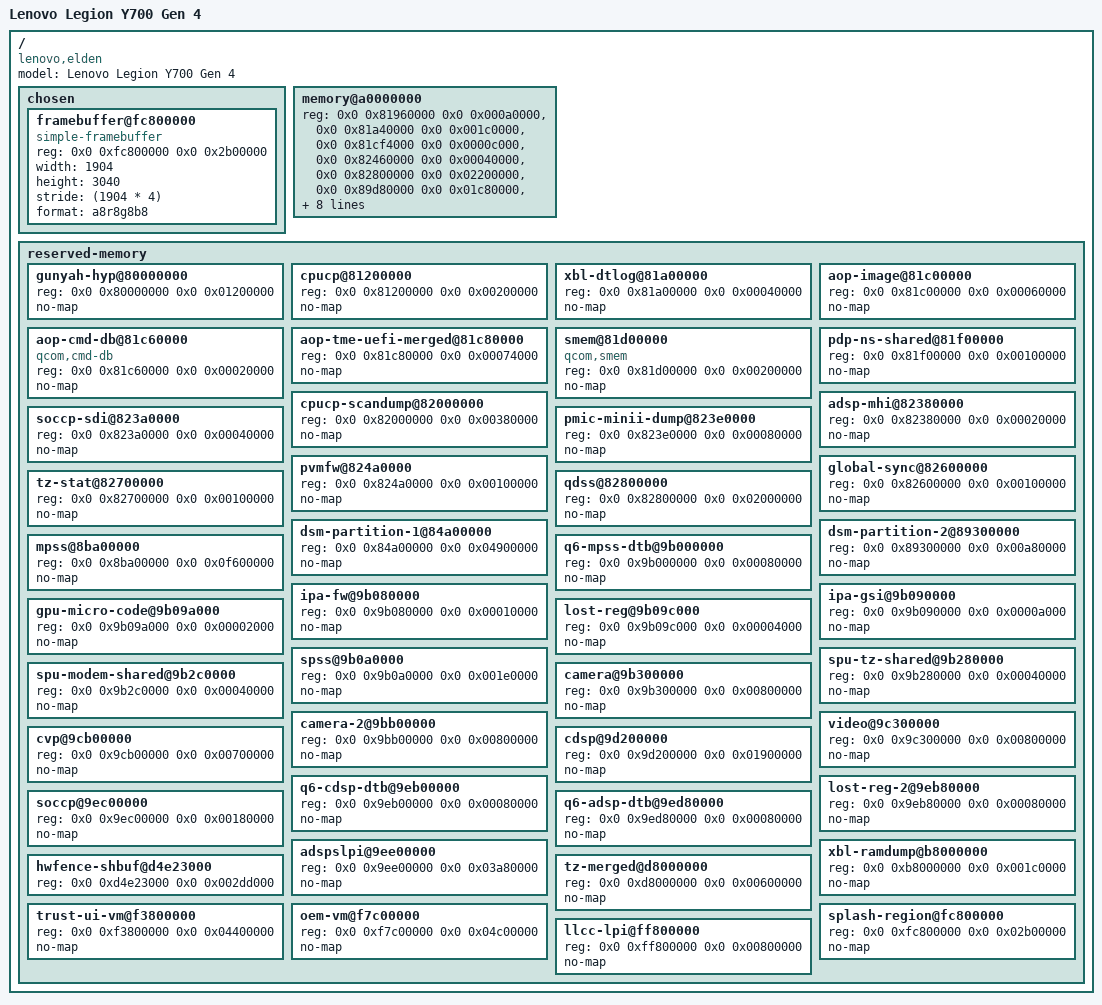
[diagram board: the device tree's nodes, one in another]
// SPDX-License-Identifier: BSD-3-Clause
//
// Sanitised elden firmware memory handoff description.
//
// This is not the raw FDT copied from a device and it is not installed into
// the phase 1 firmware. It normalises the live 12 GiB memory and reserved
// ranges captured from the target device, cross-checked against:
//
//   h0cheung/tb322fc-linux-kernel
//   arch/arm64/boot/dts/qcom/sm8750-lenovo-elden.dts
//   commit 6f97250ead155fc3b980856323e99a4623dae73d
//
// The raw device tree is local-only. This sanitised source allows the memory
// and framebuffer handoff to be reviewed, compiled and compared with a live
// FDT without publishing a device state dump.

/dts-v1/;

/ {
	model = "Lenovo Legion Y700 Gen 4";
	compatible = "lenovo,elden", "qcom,sm8750";
	#address-cells = <2>;
	#size-cells = <2>;

	chosen {
		#address-cells = <2>;
		#size-cells = <2>;
		ranges;

		framebuffer@fc800000 {
			compatible = "simple-framebuffer";
			reg = <0x0 0xfc800000 0x0 0x2b00000>;
			width = <1904>;
			height = <3040>;
			stride = <(1904 * 4)>;
			format = "a8r8g8b8";
		};
	};

	// Exact non-empty RAM ranges from the captured live FDT. The zero-length
	// D8600000 placeholder is intentionally omitted.
	memory@a0000000 {
		device_type = "memory";
		reg = <0x0 0x81960000 0x0 0x000a0000>,
		      <0x0 0x81a40000 0x0 0x001c0000>,
		      <0x0 0x81cf4000 0x0 0x0000c000>,
		      <0x0 0x82460000 0x0 0x00040000>,
		      <0x0 0x82800000 0x0 0x02200000>,
		      <0x0 0x89d80000 0x0 0x01c80000>,
		      <0x0 0xa2880000 0x0 0x15780000>,
		      <0x0 0xb81c0000 0x0 0x1cc63000>,
		      <0x0 0xd5100000 0x0 0x02f00000>,
		      <0x0 0xe3720000 0x0 0x1c0e0000>,
		      <0x8 0x80000000 0x0 0x2f900000>,
		      <0x8 0xb0000000 0x0 0x07500000>,
		      <0x8 0xc0000000 0x0 0xc0000000>,
		      <0x9 0x80000000 0x1 0x80000000>;
	};

	reserved-memory {
		#address-cells = <2>;
		#size-cells = <2>;
		ranges;

		gunyah-hyp@80000000 {
			reg = <0x0 0x80000000 0x0 0x01200000>;
			no-map;
		};

		cpucp@81200000 {
			reg = <0x0 0x81200000 0x0 0x00200000>;
			no-map;
		};

		xbl-dtlog@81a00000 {
			reg = <0x0 0x81a00000 0x0 0x00040000>;
			no-map;
		};

		aop-image@81c00000 {
			reg = <0x0 0x81c00000 0x0 0x00060000>;
			no-map;
		};

		aop-cmd-db@81c60000 {
			compatible = "qcom,cmd-db";
			reg = <0x0 0x81c60000 0x0 0x00020000>;
			no-map;
		};

		aop-tme-uefi-merged@81c80000 {
			reg = <0x0 0x81c80000 0x0 0x00074000>;
			no-map;
		};

		smem@81d00000 {
			compatible = "qcom,smem";
			reg = <0x0 0x81d00000 0x0 0x00200000>;
			no-map;
		};

		pdp-ns-shared@81f00000 {
			reg = <0x0 0x81f00000 0x0 0x00100000>;
			no-map;
		};

		cpucp-scandump@82000000 {
			reg = <0x0 0x82000000 0x0 0x00380000>;
			no-map;
		};

		adsp-mhi@82380000 {
			reg = <0x0 0x82380000 0x0 0x00020000>;
			no-map;
		};

		soccp-sdi@823a0000 {
			reg = <0x0 0x823a0000 0x0 0x00040000>;
			no-map;
		};

		pmic-minii-dump@823e0000 {
			reg = <0x0 0x823e0000 0x0 0x00080000>;
			no-map;
		};

		pvmfw@824a0000 {
			reg = <0x0 0x824a0000 0x0 0x00100000>;
			no-map;
		};

		global-sync@82600000 {
			reg = <0x0 0x82600000 0x0 0x00100000>;
			no-map;
		};

		tz-stat@82700000 {
			reg = <0x0 0x82700000 0x0 0x00100000>;
			no-map;
		};

		qdss@82800000 {
			reg = <0x0 0x82800000 0x0 0x02000000>;
			no-map;
		};

		dsm-partition-1@84a00000 {
			reg = <0x0 0x84a00000 0x0 0x04900000>;
			no-map;
		};

		dsm-partition-2@89300000 {
			reg = <0x0 0x89300000 0x0 0x00a80000>;
			no-map;
		};

		mpss@8ba00000 {
			reg = <0x0 0x8ba00000 0x0 0x0f600000>;
			no-map;
		};

		q6-mpss-dtb@9b000000 {
			reg = <0x0 0x9b000000 0x0 0x00080000>;
			no-map;
		};

		ipa-fw@9b080000 {
			reg = <0x0 0x9b080000 0x0 0x00010000>;
			no-map;
		};

		ipa-gsi@9b090000 {
			reg = <0x0 0x9b090000 0x0 0x0000a000>;
			no-map;
		};

		gpu-micro-code@9b09a000 {
			reg = <0x0 0x9b09a000 0x0 0x00002000>;
			no-map;
		};

		lost-reg@9b09c000 {
			reg = <0x0 0x9b09c000 0x0 0x00004000>;
			no-map;
		};

		spss@9b0a0000 {
			reg = <0x0 0x9b0a0000 0x0 0x001e0000>;
			no-map;
		};

		spu-tz-shared@9b280000 {
			reg = <0x0 0x9b280000 0x0 0x00040000>;
			no-map;
		};

		spu-modem-shared@9b2c0000 {
			reg = <0x0 0x9b2c0000 0x0 0x00040000>;
			no-map;
		};

		camera@9b300000 {
			reg = <0x0 0x9b300000 0x0 0x00800000>;
			no-map;
		};

		camera-2@9bb00000 {
			reg = <0x0 0x9bb00000 0x0 0x00800000>;
			no-map;
		};

		video@9c300000 {
			reg = <0x0 0x9c300000 0x0 0x00800000>;
			no-map;
		};

		cvp@9cb00000 {
			reg = <0x0 0x9cb00000 0x0 0x00700000>;
			no-map;
		};

		cdsp@9d200000 {
			reg = <0x0 0x9d200000 0x0 0x01900000>;
			no-map;
		};

		q6-cdsp-dtb@9eb00000 {
			reg = <0x0 0x9eb00000 0x0 0x00080000>;
			no-map;
		};

		lost-reg-2@9eb80000 {
			reg = <0x0 0x9eb80000 0x0 0x00080000>;
			no-map;
		};

		soccp@9ec00000 {
			reg = <0x0 0x9ec00000 0x0 0x00180000>;
			no-map;
		};

		q6-adsp-dtb@9ed80000 {
			reg = <0x0 0x9ed80000 0x0 0x00080000>;
			no-map;
		};

		adspslpi@9ee00000 {
			reg = <0x0 0x9ee00000 0x0 0x03a80000>;
			no-map;
		};

		xbl-ramdump@b8000000 {
			reg = <0x0 0xb8000000 0x0 0x001c0000>;
			no-map;
		};

		hwfence-shbuf@d4e23000 {
			reg = <0x0 0xd4e23000 0x0 0x002dd000>;
		};

		tz-merged@d8000000 {
			reg = <0x0 0xd8000000 0x0 0x00600000>;
			no-map;
		};

		trust-ui-vm@f3800000 {
			reg = <0x0 0xf3800000 0x0 0x04400000>;
			no-map;
		};

		oem-vm@f7c00000 {
			reg = <0x0 0xf7c00000 0x0 0x04c00000>;
			no-map;
		};

		splash-region@fc800000 {
			reg = <0x0 0xfc800000 0x0 0x02b00000>;
			no-map;
		};

		llcc-lpi@ff800000 {
			reg = <0x0 0xff800000 0x0 0x00800000>;
			no-map;
		};

	};
};
